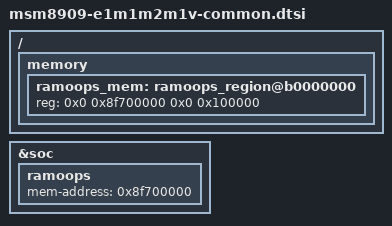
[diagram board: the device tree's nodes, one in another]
/* Copyright (c) 2014, The Linux Foundation. All rights reserved.
 *
 * This program is free software; you can redistribute it and/or modify
 * it under the terms of the GNU General Public License version 2 and
 * only version 2 as published by the Free Software Foundation.
 *
 * This program is distributed in the hope that it will be useful,
 * but WITHOUT ANY WARRANTY; without even the implied warranty of
 * MERCHANTABILITY or FITNESS FOR A PARTICULAR PURPOSE.  See the
 * GNU General Public License for more details.
 */

/ {
	memory {
		ramoops_mem: ramoops_region@b0000000 {
			reg = <0x0 0x8f700000 0x0 0x100000>;
		};
	};
};

&soc {
	ramoops {
		mem-address = <0x8f700000>;
	};
};
